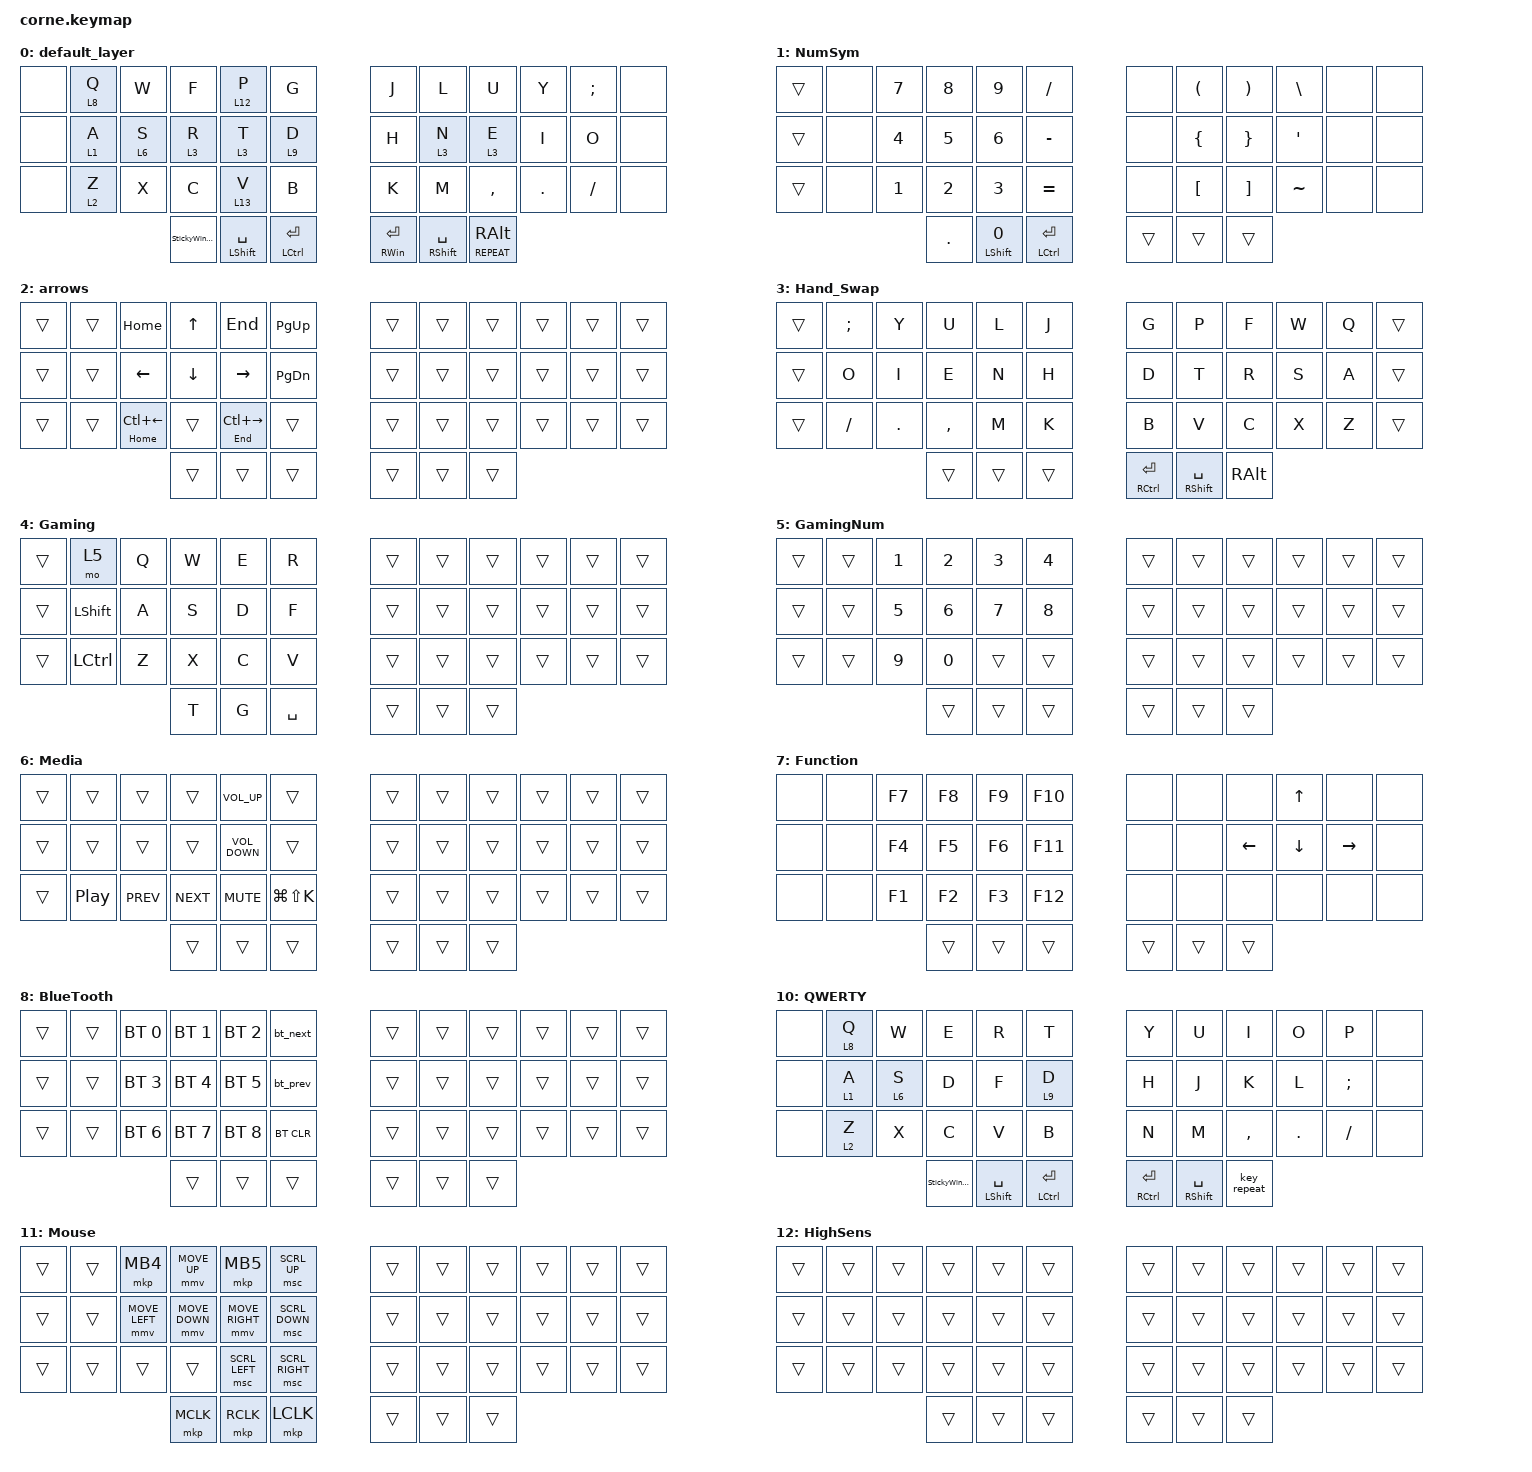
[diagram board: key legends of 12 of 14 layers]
/*
 * Copyright (c) 2020 The ZMK Contributors
 *
 * SPDX-License-Identifier: MIT
 */

#include <dt-bindings/zmk/mouse.h>
#include <behaviors.dtsi>
#include <dt-bindings/zmk/bt.h>
#include <dt-bindings/zmk/keys.h>
#include <dt-bindings/zmk/pointing.h>

/ {
    combos {
        compatible = "zmk,combos";

        Tab {
            bindings = <&kp TAB>;
            key-positions = <14 16>;
        };

        MoveWindowRight {
            bindings = <&kp LG(RIGHT)>;
            key-positions = <3 4 5>;
        };

        MoveWindowLeft {
            bindings = <&kp LG(LEFT)>;
            key-positions = <2 3 1>;
        };

        Maximize {
            bindings = <&kp LG(UP_ARROW)>;
            key-positions = <2 3 4>;
        };

        Minimize {
            bindings = <&kp LG(DOWN)>;
            key-positions = <28 27 26>;
        };

        AppView {
            bindings = <&kp LA(TAB)>;
            key-positions = <14 15 16>;
        };

        OpenApp {
            bindings = <&kp LA(SPACE)>;
            key-positions = <16 15 14 13>;
        };

        Brace {
            bindings = <&kp LEFT_PARENTHESIS>;
            key-positions = <8 7>;
        };

        EndBrace {
            bindings = <&kp RIGHT_PARENTHESIS>;
            key-positions = <9 8>;
        };

        CurlyBrace {
            bindings = <&kp LEFT_BRACE>;
            key-positions = <20 19>;
        };

        EndCurlyBrace {
            bindings = <&kp RIGHT_BRACE>;
            key-positions = <21 20>;
        };

        SquareBrace {
            bindings = <&kp LEFT_BRACKET>;
            key-positions = <32 31>;
        };

        EndSquareBrace {
            bindings = <&kp RIGHT_BRACKET>;
            key-positions = <33 32>;
        };

        Backspace {
            bindings = <&kp BACKSPACE>;
            key-positions = <14 15>;
            layers = <0 7 1 7 7 2>;
        };

        Delete {
            bindings = <&kp DELETE>;
            key-positions = <16 15>;
            layers = <0 1 7 7 7 2 8>;
        };

        Escape {
            bindings = <&kp ESC>;
            key-positions = <1 2 3 4>;
        };

        Gaming {
            bindings = <&tog 4>;
            key-positions = <16 14 13>;
        };

        Right_Hand_BKSPC {
            bindings = <&kp BACKSPACE>;
            key-positions = <9 10>;
        };

        Shut_Down {
            bindings = <&Shut_Down>;
            key-positions = <1 25 14 27>;
        };

        Function {
            bindings = <&mo 7>;
            key-positions = <13 38>;
            layers = <0>;
        };

        LessThan {
            bindings = <&kp LESS_THAN>;
            key-positions = <37 31 32>;
        };

        MoreThan {
            bindings = <&kp GREATER_THAN>;
            key-positions = <37 32 33>;
        };

        QWERTY {
            bindings = <&tog 10>;
            key-positions = <17 16 14>;
        };

        MiddleClick {
            bindings = <&mkp MCLK>;
            key-positions = <16 17>;
            layers = <0>;
        };

        TrackpadToggle {
            bindings = <&tp_tog>;
            key-positions = <18 19>;
            require-prior-idle-ms = <150>;
        };
    };

    macros {
        Shut_Down: Shut_Down {
            compatible = "zmk,behavior-macro";
            #binding-cells = <0>;
            bindings =
                <&macro_tap>,
                <&kp LG(X)>,
                <&macro_wait_time 100>,
                <&kp U>,
                <&macro_wait_time 100>,
                <&kp U>;
        };
    };

    behaviors {
        StickyKey: StickyKey {
            compatible = "zmk,behavior-sticky-key";
            bindings = <&kp>;
            #binding-cells = <1>;
            release-after-ms = <500>;
        };

        StickyWinKey: StickyWinKey {
            compatible = "zmk,behavior-tap-dance";
            #binding-cells = <0>;
            bindings = <&kp LEFT_ALT>, <&StickyKey LEFT_WIN>;
        };

        // Trackpad on/off, remembered through sleep (modules/trackpad_toggle).
        // Name must stay 8 characters or fewer: ZMK's split protocol truncates global
        // behavior names to 8, so a longer one can't be found on the right half.

        tp_tog: tp_tog {
            compatible = "zmk,behavior-trackpad-toggle";
            #binding-cells = <0>;
        };

        // Next / previous Bluetooth profile, skipping empty ones (modules/bt_cycle).

        bt_next: bt_next {
            compatible = "zmk,behavior-bt-cycle";
            #binding-cells = <0>;
        };

        bt_prev: bt_prev {
            compatible = "zmk,behavior-bt-cycle";
            #binding-cells = <0>;
            reverse;
        };
    };

    keymap {
        compatible = "zmk,keymap";

        default_layer {
            // -----------------------------------------------------------------------------------------
            // |  TAB |  Q  |  W  |  E  |  R  |  T  |   |  Y  |  U   |  I  |  O  |  P  | BKSP |
            // | CTRL |  A  |  S  |  D  |  F  |  G  |   |  H  |  J   |  K  |  L  |  ;  |  '   |
            // | SHFT |  Z  |  X  |  C  |  V  |  B  |   |  N  |  M   |  ,  |  .  |  /  | ESC  |
            //                    | GUI | LWR | SPC |   | ENT | RSE  | ALT |

            bindings = <
&none  &lt 8 Q  &kp W    &kp F          &lt 12 P              &kp G                     &kp J                &kp L                  &kp U                   &kp Y    &kp SEMICOLON  &none
&none  &lt 1 A  &lt 6 S  &lt 3 R        &lt 3 T               &lt 9 D                   &kp H                &lt 3 N                &lt 3 E                 &kp I    &kp O          &none
&none  &lt 2 Z  &kp X    &kp C          &lt 13 V              &kp B                     &kp K                &kp M                  &kp COMMA               &kp DOT  &kp FSLH       &none
                         &StickyWinKey  &mt LEFT_SHIFT SPACE  &mt LEFT_CONTROL ENTER    &mt RIGHT_WIN ENTER  &mt RIGHT_SHIFT SPACE  &mt C_REPEAT RIGHT_ALT
            >;
        };

        NumSym {
            // -----------------------------------------------------------------------------------------
            // |  TAB |  1  |  2  |  3  |  4  |  5  |   |  6  |  7  |  8  |  9  |  0  | BKSP |
            // | BTCLR| BT1 | BT2 | BT3 | BT4 | BT5 |   | LFT | DWN |  UP | RGT |     |      |
            // | SHFT |     |     |     |     |     |   |     |     |     |     |     |      |
            //                    | GUI |     | SPC |   | ENT |     | ALT |

            bindings = <
&trans  &none  &kp N7  &kp N8      &kp N9             &kp SLASH          &none   &kp LEFT_PARENTHESIS  &kp RIGHT_PARENTHESIS  &kp BACKSLASH     &none  &none
&trans  &none  &kp N4  &kp N5      &kp NUMBER_6       &kp MINUS          &none   &kp LEFT_BRACE        &kp RIGHT_BRACE        &kp SINGLE_QUOTE  &none  &none
&trans  &none  &kp N1  &kp N2      &kp N3             &kp EQUAL          &none   &kp LEFT_BRACKET      &kp RIGHT_BRACKET      &kp TILDE         &none  &none
                       &kp PERIOD  &mt LEFT_SHIFT N0  &mt LCTRL ENTER    &trans  &trans                &trans
            >;

            label = "NumSym";
        };

        arrows {
            bindings = <
&trans  &trans  &kp HOME                 &kp UP    &kp END                  &kp PAGE_UP      &trans  &trans  &trans  &trans  &trans  &trans
&trans  &trans  &kp LEFT                 &kp DOWN  &kp RIGHT                &kp PAGE_DOWN    &trans  &trans  &trans  &trans  &trans  &trans
&trans  &trans  &mt HOME LC(LEFT_ARROW)  &trans    &mt END LC(RIGHT_ARROW)  &trans           &trans  &trans  &trans  &trans  &trans  &trans
                                         &trans    &trans                   &trans           &trans  &trans  &trans
            >;

            label = "arrows";
        };

        Hand_Swap {
            bindings = <
&trans  &kp SEMI  &kp Y    &kp U      &kp L   &kp J     &kp G            &kp P                  &kp F          &kp W  &kp Q  &trans
&trans  &kp O     &kp I    &kp E      &kp N   &kp H     &kp D            &kp T                  &kp R          &kp S  &kp A  &trans
&trans  &kp FSLH  &kp DOT  &kp COMMA  &kp M   &kp K     &kp B            &kp V                  &kp C          &kp X  &kp Z  &trans
                           &trans     &trans  &trans    &mt RCTRL ENTER  &mt RIGHT_SHIFT SPACE  &kp RIGHT_ALT
            >;
        };

        Gaming {
            bindings = <
&trans  &mo 5           &kp Q  &kp W  &kp E  &kp R        &trans  &trans  &trans  &trans  &trans  &trans
&trans  &kp LEFT_SHIFT  &kp A  &kp S  &kp D  &kp F        &trans  &trans  &trans  &trans  &trans  &trans
&trans  &kp LCTRL       &kp Z  &kp X  &kp C  &kp V        &trans  &trans  &trans  &trans  &trans  &trans
                               &kp T  &kp G  &kp SPACE    &trans  &trans  &trans
            >;

            label = "Gaming";
        };

        GamingNum {
            bindings = <
&trans  &trans  &kp N1  &kp N2  &kp N3  &kp N4    &trans  &trans  &trans  &trans  &trans  &trans
&trans  &trans  &kp N5  &kp N6  &kp N7  &kp N8    &trans  &trans  &trans  &trans  &trans  &trans
&trans  &trans  &kp N9  &kp N0  &trans  &trans    &trans  &trans  &trans  &trans  &trans  &trans
                        &trans  &trans  &trans    &trans  &trans  &trans
            >;
        };

        Media {
            bindings = <
&trans  &trans            &trans      &trans      &kp C_VOLUME_UP    &trans           &trans  &trans  &trans  &trans  &trans  &trans
&trans  &trans            &trans      &trans      &kp C_VOLUME_DOWN  &trans           &trans  &trans  &trans  &trans  &trans  &trans
&trans  &kp C_PLAY_PAUSE  &kp C_PREV  &kp C_NEXT  &kp C_MUTE         &kp LG(LS(K))    &trans  &trans  &trans  &trans  &trans  &trans
                                      &trans      &trans             &trans           &trans  &trans  &trans
            >;

            label = "Media";
        };

        Function {
            bindings = <
&none  &none  &kp F7  &kp F8  &kp F9  &kp F10    &none   &none   &none     &kp UP    &none      &none
&none  &none  &kp F4  &kp F5  &kp F6  &kp F11    &none   &none   &kp LEFT  &kp DOWN  &kp RIGHT  &none
&none  &none  &kp F1  &kp F2  &kp F3  &kp F12    &none   &none   &none     &none     &none      &none
                      &trans  &trans  &trans     &trans  &trans  &trans
            >;

            label = "Function";
        };

        BlueTooth {
            bindings = <
&trans  &trans  &bt BT_SEL 0  &bt BT_SEL 1  &bt BT_SEL 2  &bt_next      &trans  &trans  &trans  &trans  &trans  &trans
&trans  &trans  &bt BT_SEL 3  &bt BT_SEL 4  &bt BT_SEL 5  &bt_prev      &trans  &trans  &trans  &trans  &trans  &trans
&trans  &trans  &bt BT_SEL 6  &bt BT_SEL 7  &bt BT_SEL 8  &bt BT_CLR    &trans  &trans  &trans  &trans  &trans  &trans
                              &trans        &trans        &trans        &trans  &trans  &trans
            >;
        };

        VSCode {
            bindings = <
&trans  &trans  &kp LS(LC(L))      &kp LS(LA(RIGHT))  &kp LA(UP_ARROW)  &trans    &trans  &trans  &trans  &trans  &trans  &trans
&trans  &trans  &kp LC(L)          &kp LS(LA(LEFT))   &kp LA(DOWN)      &trans    &trans  &trans  &trans  &trans  &trans  &trans
&trans  &trans  &kp LS(LA(LC(S)))  &trans             &trans            &trans    &trans  &trans  &trans  &trans  &trans  &trans
                                   &trans             &trans            &trans    &trans  &trans  &trans
            >;
        };

        QWERTY {
            bindings = <
&none  &lt 8 Q  &kp W    &kp E          &kp R                 &kp T                     &kp Y            &kp U                  &kp I        &kp O    &kp P     &none
&none  &lt 1 A  &lt 6 S  &kp D          &kp F                 &lt 9 D                   &kp H            &kp J                  &kp K        &kp L    &kp SEMI  &none
&none  &lt 2 Z  &kp X    &kp C          &kp V                 &kp B                     &kp N            &kp M                  &kp COMMA    &kp DOT  &kp FSLH  &none
                         &StickyWinKey  &mt LEFT_SHIFT SPACE  &mt LEFT_CONTROL ENTER    &mt RCTRL ENTER  &mt RIGHT_SHIFT SPACE  &key_repeat
            >;
        };

        Mouse {
            bindings = <
&trans  &trans  &mkp MB4        &mmv MOVE_UP    &mkp MB5         &msc SCRL_UP       &trans  &trans  &trans  &trans  &trans  &trans
&trans  &trans  &mmv MOVE_LEFT  &mmv MOVE_DOWN  &mmv MOVE_RIGHT  &msc SCRL_DOWN     &trans  &trans  &trans  &trans  &trans  &trans
&trans  &trans  &trans          &trans          &msc SCRL_LEFT   &msc SCRL_RIGHT    &trans  &trans  &trans  &trans  &trans  &trans
                                &mkp MCLK       &mkp RCLK        &mkp LCLK          &trans  &trans  &trans
            >;
        };

        HighSens {
            bindings = <
&trans  &trans  &trans  &trans  &trans  &trans    &trans  &trans  &trans  &trans  &trans  &trans
&trans  &trans  &trans  &trans  &trans  &trans    &trans  &trans  &trans  &trans  &trans  &trans
&trans  &trans  &trans  &trans  &trans  &trans    &trans  &trans  &trans  &trans  &trans  &trans
                        &trans  &trans  &trans    &trans  &trans  &trans
            >;

            label = "HighSens";
        };

        LowSens {
            bindings = <
&trans  &trans  &trans  &trans  &trans  &trans    &trans  &trans  &trans  &trans  &trans  &trans
&trans  &trans  &trans  &trans  &trans  &trans    &trans  &trans  &trans  &trans  &trans  &trans
&trans  &trans  &trans  &trans  &trans  &trans    &trans  &trans  &trans  &trans  &trans  &trans
                        &trans  &trans  &trans    &trans  &trans  &trans
            >;

            label = "LowSens";
        };
    };
};
